AUTOSAR XML (schema 4-0-3)
package /ComponentTypes
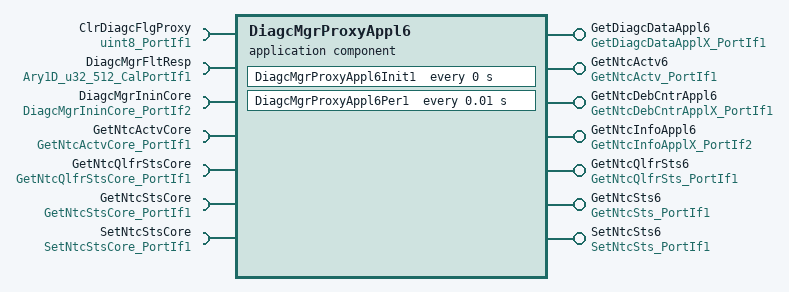
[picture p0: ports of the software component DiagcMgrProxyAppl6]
  application sw component type DiagcMgrProxyAppl6
    7 x provide port, all with server-com-spec{operation=Oper, queue-length=1}:
      GetDiagcDataAppl6: provided-interface=GetDiagcDataApplX_PortIf1
      GetNtcActv6: provided-interface=GetNtcActv_PortIf1
      GetNtcDebCntrAppl6: provided-interface=GetNtcDebCntrApplX_PortIf1
      GetNtcInfoAppl6: provided-interface=GetNtcInfoApplX_PortIf2
      GetNtcQlfrSts6: provided-interface=GetNtcQlfrSts_PortIf1
      GetNtcSts6: provided-interface=GetNtcSts_PortIf1
      SetNtcSts6: provided-interface=SetNtcSts_PortIf1
    7 x require port:
      ClrDiagcFlgProxy: nonqueued-receiver-com-spec{data-element=Val, filter=data-filter-type=ALWAYS, init-value=0}, required-interface=uint8_PortIf1
      DiagcMgrFltResp: parameter-require-com-spec{init-value=[0, 2147487488, 2147487488, 2147487488, 2147487488, 2147487488, 2147487488, 2147487488, 2147487488, 2147487488, 2147487488, 2147487488, 2147487488, 2147487488, 2147487488, 2147487488, 2147487488, 2147487488, 2147487488, 2147487488, 2147487488, 2147487488, 2147487488, 2147487488, 2147487488, 2147487488, 2147487488, 2147487488, 2147487488, 2147487488, 2147487488, 2147487488, 2147487488, 2147487488, 2147487488, 2147487488, 2147487488, 2147487488, 2147487488, 2147487488, 2147487488, 2147487488, 2147487488, 2147487488, 2147487488, 2147487488, 2147487488, 2147487488, 2147487488, 2147487488, 2147487488, 2147487488, 2147487488, 2147487488, 2147487488, 2147487488, 2147487488, 2147487488, 2147487488, 2147487488, 2147487488, 2147487488, 2147487488, 2147487488, 2147487488, 2147487488, 2147487488, 2147487488, 2147487488, 2147487488, 2147487488, 2147487488, 2147487488, 2147487488, 2147487488, 2147487488, 2147487488, 2147487488, 2147487488, 2147487488, 2147487488, 2147487488, 2147487488, 2147487488, 2147487488, 2147487488, 2147487488, 2147487488, 2147487488, 2147487488, 2147487488, 2147487488, 2147487488, 2147487488, 2147487488, 2147487488, 2147487488, 2147487488, 2147487488, 2147487488, 2147487488, 2147487488, 2147487488, 2147487488, 2147487488, 2147487488, 2147487488, 2147487488, 2147487488, 2147487488, 2147487488, 2147487488, 2147487488, 2147487488, 2147487488, 2147487488, 2147487488, 2147487488, 2147487488, 2147487488, 2147487488, 2147487488, 2147487488, 2147487488, 2147487488, 2147487488, 2147487488, 2147487488, 2147487488, 2147487488, 2147487488, 2147487488, 2147487488, 2147487488, 2147487488, 2147487488, 2147487488, 2147487488, 2147487488, 2147487488, 2147487488, 2147487488, 2147487488, 2147487488, 2147487488, 2147487488, 2147487488, 2147487488, 2147487488, 2147487488, 2147487488, 2147487488, 2147487488, 2147487488, 2147487488, 2147487488, 2147487488, 2147487488, 2147487488, 2147487488, 2147487488, 2147487488, 2147487488, 2147487488, 2147487488, 2147487488, 2147487488, 2147487488, 2147487488, 2147487488, 2147487488, 2147487488, 2147487488, 2147487488, 2147487488, 2147487488, 2147487488, 2147487488, 2147487488, 2147487488, 2147487488, 2147487488, 2147487488, 2147487488, 2147487488, 2147487488, 2147487488, 2147487488, 2147487488, 2147487488, 2147487488, 2147487488, 2147487488, 2147487488, 2147487488, 2147487488, 2147487488, 2147487488, 2147487488, 2147487488, 2147487488, 2147487488, 2147487488, 2147487488, 2147487488, 2147487488, 2147487488, 2147487488, 2147487488, 2147487488, 2147487488, 2147487488, 2147487488, 2147487488, 2147487488, 2147487488, 2147487488, 2147487488, 2147487488, 2147487488, 2147487488, 2147487488, 2147487488, 2147487488, 2147487488, 2147487488, 2147487488, 2147487488, 2147487488, 2147487488, 2147487488, 2147487488, 2147487488, 2147487488, 2147487488, 2147487488, 2147487488, 2147487488, 2147487488, 2147487488, 2147487488, 2147487488, 2147487488, 2147487488, 2147487488, 2147487488, 2147487488, 2147487488, 2147487488, 2147487488, 2147487488, 2147487488, 2147487488, 2147487488, 2147487488, 2147487488, 2147487488, 2147487488, 2147487488, 2147487488, 2147487488, 2147487488, 2147487488, 2147487488, 2147487488, 2147487488, 2147487488, 2147487488, 2147487488, 2147487488, 2147487488, 2147487488, 2147487488, 2147487488, 2147487488, 2147487488, 2147487488, 2147487488, 2147487488, 2147487488, 2147487488, 2147487488, 2147487488, 2147487488, 2147487488, 2147487488, 2147487488, 2147487488, 2147487488, 2147487488, 2147487488, 2147487488, 2147487488, 2147487488, 2147487488, 2147487488, 2147487488, 2147487488, 2147487488, 2147487488, 2147487488, 2147487488, 2147487488, 2147487488, 2147487488, 2147487488, 2147487488, 2147487488, 2147487488, 2147487488, 2147487488, 2147487488, 2147487488, 2147487488, 2147487488, 2147487488, 2147487488, 2147487488, 2147487488, 2147487488, 2147487488, 2147487488, 2147487488, 2147487488, 2147487488, 2147487488, 2147487488, 2147487488, 2147487488, 2147487488, 2147487488, 2147487488, 2147487488, 2147487488, 2147487488, 2147487488, 2147487488, 2147487488, 2147487488, 2147487488, 2147487488, 2147487488, 2147487488, 2147487488, 2147487488, 2147487488, 2147487488, 2147487488, 2147487488, 2147487488, 2147487488, 2147487488, 2147487488, 2147487488, 2147487488, 2147487488, 2147487488, 2147487488, 2147487488, 2147487488, 2147487488, 2147487488, 2147487488, 2147487488, 2147487488, 2147487488, 2147487488, 2147487488, 2147487488, 2147487488, 2147487488, 2147487488, 2147487488, 2147487488, 2147487488, 2147487488, 2147487488, 2147487488, 2147487488, 2147487488, 2147487488, 2147487488, 2147487488, 2147487488, 2147487488, 2147487488, 2147487488, 2147487488, 2147487488, 2147487488, 2147487488, 2147487488, 2147487488, 2147487488, 2147487488, 2147487488, 2147487488, 2147487488, 2147487488, 2147487488, 2147487488, 2147487488, 2147487488, 2147487488, 2147487488, 2147487488, 2147487488, 2147487488, 2147487488, 2147487488, 2147487488, 2147487488, 2147487488, 2147487488, 2147487488, 2147487488, 2147487488, 2147487488, 2147487488, 2147487488, 2147487488, 2147487488, 2147487488, 2147487488, 2147487488, 2147487488, 2147487488, 2147487488, 2147487488, 2147487488, 2147487488, 2147487488, 2147487488, 2147487488, 2147487488, 2147487488, 2147487488, 2147487488, 2147487488, 2147487488, 2147487488, 2147487488, 2147487488, 2147487488, 2147487488, 2147487488, 2147487488, 2147487488, 2147487488, 2147487488, 2147487488, 2147487488, 2147487488, 2147487488, 2147487488, 2147487488, 2147487488, 2147487488, 2147487488, 2147487488, 2147487488, 2147487488, 2147487488, 2147487488, 2147487488, 2147487488, 2147487488, 2147487488, 2147487488, 2147487488, 2147487488, 2147487488, 2147487488, 2147487488, 2147487488, 2147487488, 2147487488, 2147487488, 2147487488, 2147487488, 2147487488, 2147487488, 2147487488, 2147487488, 2147487488, 2147487488, 2147487488, 2147487488, 2147487488, 2147487488, 2147487488, 2147487488, 2147487488, 2147487488, 2147487488, 2147487488, 2147487488, 2147487488, 2147487488, 2147487488, 2147487488, 2147487488, 2147487488, 2147487488, 2147487488, 2147487488, 2147487488, 2147487488, 2147487488, 2147487488, 2147487488, 2147487488], parameter=Ary1D}, required-interface=Ary1D_u32_512_CalPortIf1
      DiagcMgrIninCore: required-interface=DiagcMgrIninCore_PortIf2
      GetNtcActvCore: required-interface=GetNtcActvCore_PortIf1
      GetNtcQlfrStsCore: required-interface=GetNtcQlfrStsCore_PortIf1
      GetNtcStsCore: required-interface=GetNtcStsCore_PortIf1
      SetNtcStsCore: required-interface=SetNtcStsCore_PortIf1
    behavior DiagcMgrProxyAppl6_InternalBehavior
      exclusive area DiagcMgrProxyAppl6
      ar-typed-per-instance-memorys:
        5 x data:
          DiagcData6: sw-calibration-access=READ-ONLY, type=DiagcDataRec1
          DiagcMgrNtcInfo6Ary: type=Ary1D_NtcInfoRec4_DiagcMgrProxyAppl6
          DiagcMgrNtcInfo6DebCntrAry: type=Ary1D_s16_DiagcMgrProxyAppl6
          PrevClrNtcFlg6: sw-calibration-access=READ-ONLY, type=uint8
          ProxySetNtcData6: sw-calibration-access=READ-ONLY, type=DiagcDataRec1
      timing event DiagcMgrProxyAppl6_InitEvent: start-on-event=DiagcMgrProxyAppl6Init1, period=0
      timing event TMT_DiagcMgrProxyAppl6Per1: start-on-event=DiagcMgrProxyAppl6Per1, period=0.01
      7 x operation invoked event:
        OIT_GetDiagcDataAppl6_Oper_GetDiagcDataAppl6_Oper: start-on-event=GetDiagcDataAppl6_Oper, operation=GetDiagcDataAppl6.Oper
        OIT_GetNtcActv6_Oper_GetNtcActv6_Oper: start-on-event=GetNtcActv6_Oper, operation=GetNtcActv6.Oper
        OIT_GetNtcDebCntrAppl6_Oper_GetNtcDebCntrAppl6_Oper: start-on-event=GetNtcDebCntrAppl6_Oper, operation=GetNtcDebCntrAppl6.Oper
        OIT_GetNtcInfoAppl6_Oper_GetNtcInfoAppl6_Oper: start-on-event=GetNtcInfoAppl6_Oper, operation=GetNtcInfoAppl6.Oper
        OIT_GetNtcQlfrSts6_Oper_GetNtcQlfrSts6_Oper: start-on-event=GetNtcQlfrSts6_Oper, operation=GetNtcQlfrSts6.Oper
        OIT_GetNtcSts6_Oper_GetNtcSts6_Oper: start-on-event=GetNtcSts6_Oper, operation=GetNtcSts6.Oper
        OIT_SetNtcSts6_Oper_SetNtcSts6_Oper: start-on-event=SetNtcSts6_Oper, operation=SetNtcSts6.Oper
      9 x runnable:
        DiagcMgrProxyAppl6Init1
          sync call SC_DiagcMgrIninCore_Oper: operation=DiagcMgrIninCore.Oper, timeout=0
        DiagcMgrProxyAppl6Per1: can-enter-exclusive-area=DiagcMgrProxyAppl6
          data-receive-point-by-arguments:
            access REC_ClrNtcFlg_Val: accessed-variable=ClrDiagcFlgProxy.Val
        GetDiagcDataAppl6_Oper: can-enter-exclusive-area=DiagcMgrProxyAppl6
        GetNtcActv6_Oper: can-be-invoked-concurrently=true
          sync call SC_GetNtcActvCore_Oper: operation=GetNtcActvCore.Oper, timeout=0
        GetNtcDebCntrAppl6_Oper
        GetNtcInfoAppl6_Oper
        GetNtcQlfrSts6_Oper: can-be-invoked-concurrently=true
          sync call SC_GetNtcQlfrStsCore_Oper: operation=GetNtcQlfrStsCore.Oper, timeout=0
        GetNtcSts6_Oper: can-be-invoked-concurrently=true
          sync call SC_GetNtcStsCore_Oper: operation=GetNtcStsCore.Oper, timeout=0
        SetNtcSts6_Oper: can-be-invoked-concurrently=true
          sync call SC_SetNtcStsCore_Oper: operation=SetNtcStsCore.Oper, timeout=0
  swc implementation DiagcMgrProxyAppl6_Implementation: behavior=DiagcMgrProxyAppl6_InternalBehavior
    code-descriptors:
      code Default: artifact-descriptors=autosar-engineering-object={short-label=Default, category=SWSRC}
